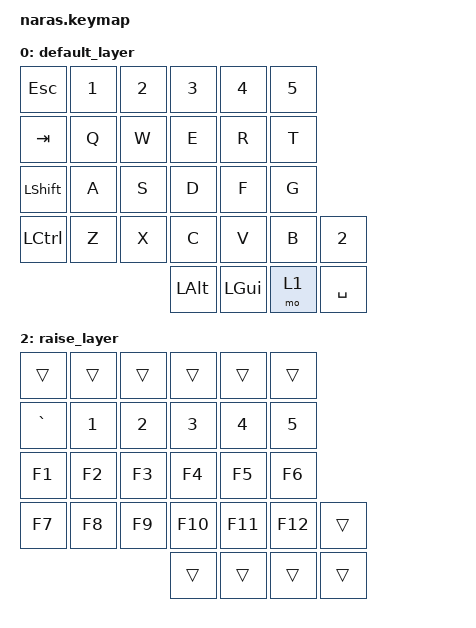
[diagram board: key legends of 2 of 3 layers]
/*
 * Copyright (c) 2020 The ZMK Contributors
 *
 * SPDX-License-Identifier: MIT
 */

#include <behaviors.dtsi>
#include <dt-bindings/zmk/keys.h>
#include <dt-bindings/zmk/bt.h>
#include <dt-bindings/zmk/ext_power.h>

/ {
    keymap {
        compatible = "zmk,keymap";

        default_layer {
// ------------------------------------------------------------------------------------------------------------
// |  ESC  |  1  |  2  |  3   |  4   |  5   |                   |  6   |  7    |  8    |  9   |   0   |   `   |
// |  TAB  |  Q  |  W  |  E   |  R   |  T   |                   |  Y   |  U    |  I    |  O   |   P   |   -   |
// |  CTRL |  A  |  S  |  D   |  F   |  G   |                   |  H   |  J    |  K    |  L   |   ;   |   '   |
// | SHIFT |  Z  |  X  |  C   |  V   |  B   |   "["  |  |  "]"  |  N   |  M    |  ,    |  .   |   /   | SHIFT |
//                     | ALT  | GUI  | LOWER|  SPACE |  | ENTER | RAISE| BSPC  | GUI   |
            bindings = <
&kp ESC   &kp N1 &kp N2 &kp N3   &kp N4   &kp N5          
&kp TAB   &kp Q  &kp W  &kp E    &kp R    &kp T           
&kp LSHFT &kp A  &kp S  &kp D    &kp F    &kp G           
&kp LCTRL &kp Z  &kp X  &kp C    &kp V    &kp B  &kp 2    
                        &kp LALT &kp LGUI &mo 1  &kp SPACE
            >;
        };

        lower_layer {
// ------------------------------------------------------------------------------------------------------------
// | BTCLR | BT1 | BT2 |  BT3 |  BT4 |  BT5 |                   |      |       |       |      |       |       |
// |  F1   |  F2 |  F3 |  F4  |  F5  |  F6  |                   |  F7  |  F8   |  F9   |  F10 |  F11  |  F12  |
// |   `   |  !  |  @  |  #   |  $   |  %   |                   |  ^   |  &    |  *    |  (   |   )   |   ~   |
// |       |     |     |      |      |      |        |  |       |      |  _    |  +    |  {   |   }   |  "|"  |
//                     |      |      |      |        |  |       |      |       |       |
            bindings = <
&bt BT_CLR &bt BT_SEL 0     &bt BT_SEL 1      &bt BT_SEL 2     
&kp F1     &kp F2           &kp F3            &kp F4           
&kp GRAVE  &kp EXCL         &kp AT            &kp HASH         
&trans     &ext_power EP_ON &ext_power EP_OFF &ext_power EP_TOG
                                              &trans           
            >;

        };

        raise_layer {
// ------------------------------------------------------------------------------------------------------------
// |       |     |     |      |      |      |                   |      |       |       |      |       |       |
// |   `   |  1  |  2  |  3   |  4   |  5   |                   |  6   |   7   |   8   |  9   |   0   |       |
// |   F1  |  F2 |  F3 |  F4  |  F5  |  F6  |                   |      |   <-  |   v   |  ^   |  ->   |       |
// |   F7  |  F8 |  F9 |  F10 |  F11 |  F12 |        |  |       |  +   |   -   |   =   |  [   |   ]   |   \   |
//                     |      |      |      |        |  |       |      |       |       |
            bindings = <
&trans    &trans &trans &trans  &trans  &trans           
&kp GRAVE &kp N1 &kp N2 &kp N3  &kp N4  &kp N5           
&kp F1    &kp F2 &kp F3 &kp F4  &kp F5  &kp F6           
&kp F7    &kp F8 &kp F9 &kp F10 &kp F11 &kp F12   &trans 
                        &trans  &trans  &trans    &trans 
            >;
        };
    };
};
